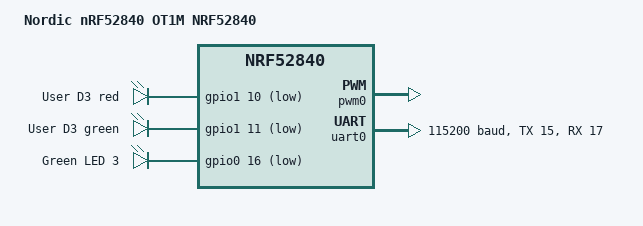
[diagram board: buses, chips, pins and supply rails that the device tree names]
/*
 *
 * SPDX-License-Identifier: Apache-2.0
 */

/dts-v1/;
#include <nordic/nrf52840_qiaa.dtsi>

/ {
	model = "Nordic nRF52840 OT1M NRF52840";
	compatible = "nordic,nrf52840-ot1m-nrf52840";

	chosen {
		zephyr,console = &uart0;
		zephyr,sram = &sram0;
		zephyr,flash = &flash0;
		zephyr,entropy = &rng;
		zephyr,code-partition = &slot0_partition;
	};

	leds {
		compatible = "gpio-leds";
		red_led: led_0 {
			gpios = <&gpio1 10 GPIO_ACTIVE_LOW>;
			label = "User D3 red";
		};
		green_led: led_1 {
			gpios = <&gpio1 11 GPIO_ACTIVE_LOW>;
			label = "User D3 green";
		};
		led3: led_3 {
			gpios = <&gpio0 16 GPIO_ACTIVE_LOW>;
			label = "Green LED 3";
		};
	};

	pwmleds {
		pwm_led3: pwm_led_3 {
			pwms = <&pwm0 16>;
		};
	};
};

&pwm0 {
	status = "okay";
	ch1-pin = <16>;
	ch1-inverted;
};

&gpio0 {
	status = "okay";
};

&gpio1 {
	status = "okay";
};

&gpiote {
	status = "okay";
};

&uart0 {
	compatible = "nordic,nrf-uart";
	status = "okay";
	current-speed = <115200>;
	tx-pin = <15>;
	rx-pin = <17>;
};

&flash0 {
	/*
	 * For more information, see:
	 * http://docs.zephyrproject.org/latest/guides/dts/index.html#flash-partitions
	 */
	partitions {
		compatible = "fixed-partitions";
		#address-cells = <1>;
		#size-cells = <1>;

		boot_partition: partition@0 {
			label = "mcuboot";
			reg = <0x000000000 0x00010000>;
		};
		slot0_partition: partition@10000 {
			label = "image-0";
			reg = <0x00010000 0x00065000>;
		};
		slot1_partition: partition@75000 {
			label = "image-1";
			reg = <0x00075000 0x00065000>;
		};
		scratch_partition: partition@da000 {
			label = "image-scratch";
			reg = <0x000da000 0x0001e000>;
		};

		/*
		 * The flash starting at 0x000f8000 and ending at
		 * 0x000fffff is reserved for use by the application.
		 */

		/*
		 * Storage partition will be used by FCB/LittleFS/NVS
		 * if enabled.
		 */
		storage_partition: partition@f8000 {
			label = "storage";
			reg = <0x000f8000 0x00008000>;
		};
	};
};
